# M3HM register map
File version: 0.1
Registers are 32-bit, read-write, reset 0x0 unless marked. A register's access mark holds for its fields unless they carry their own. Offsets are from the block's base; [hi:lo] are bit positions; {n}, {i} and the like mark numbered series.

## PG — Port G
Base 0x400C0600
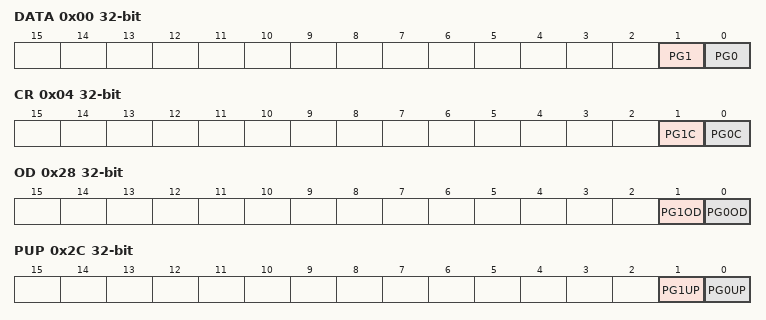
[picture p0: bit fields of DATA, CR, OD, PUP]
0x00 DATA — PG Data Register
  [1] PG1, [0] PG0
0x04 CR — PG Control Register
  [1] PG1C, [0] PG0C
0x28 OD — PG Open Drain Control Register
  [1] PG1OD, [0] PG0OD
0x2C PUP — PG Pull-up Control Register
  [1] PG1UP, [0] PG0UP
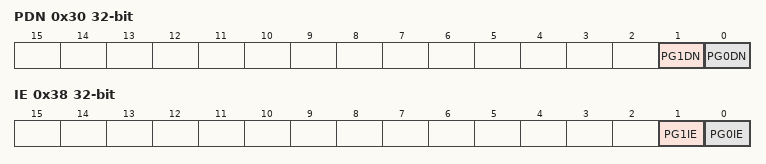
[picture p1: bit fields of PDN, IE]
0x30 PDN — PG Pull-Down Control Register
  [1] PG1DN, [0] PG0DN
0x38 IE — PG Input Enable Control Register
  [1] PG1IE, [0] PG0IE

## PH — Port H
Base 0x400C0700
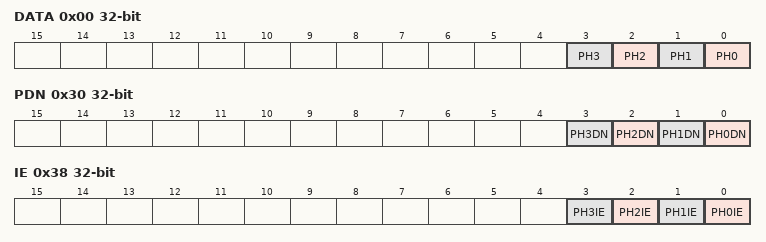
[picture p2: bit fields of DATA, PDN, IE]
0x00 DATA — PH Data Register
  [n] PH{n} (n=0..3)
0x30 PDN — PH Pull-Down Control Register
  [n] PH{n}DN (n=0..3)
0x38 IE — PH Input Enable Control Register
  [n] PH{n}IE (n=0..3)

## PJ — Port J
Base 0x400C0800
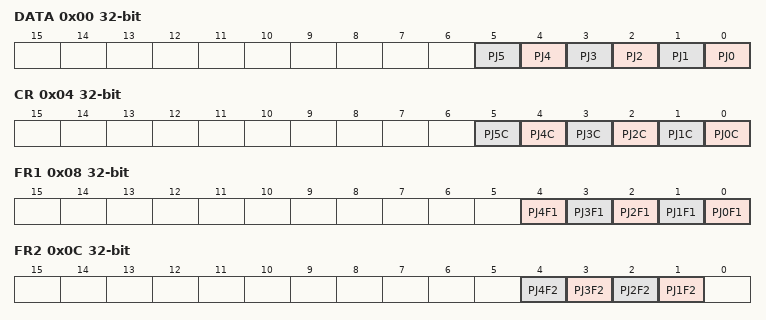
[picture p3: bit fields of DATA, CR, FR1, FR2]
0x00 DATA — PJ Data Register
  [n] PJ{n} (n=0..5)
0x04 CR — PJ Control Register
  [n] PJ{n}C (n=0..5)
0x08 FR1 — PJ Function Register 1
  [n] PJ{n}F1 (n=0..4)
0x0C FR2 — PJ Function Register 2
  [n] PJ{n}F2 (n=1..4)
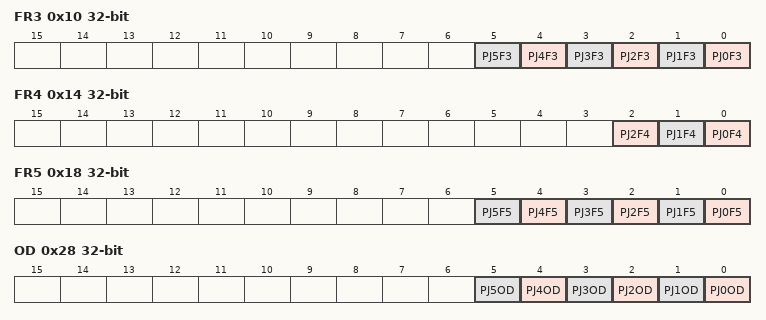
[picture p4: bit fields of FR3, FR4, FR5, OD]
0x10 FR3 — PJ Function Register 3
  [n] PJ{n}F3 (n=0..5)
0x14 FR4 — PJ Function Register 4
  [2] PJ2F4, [1] PJ1F4, [0] PJ0F4
0x18 FR5 — PJ Function Register 5
  [n] PJ{n}F5 (n=0..5)
0x28 OD — PJ Open Drain Control Register
  [n] PJ{n}OD (n=0..5)
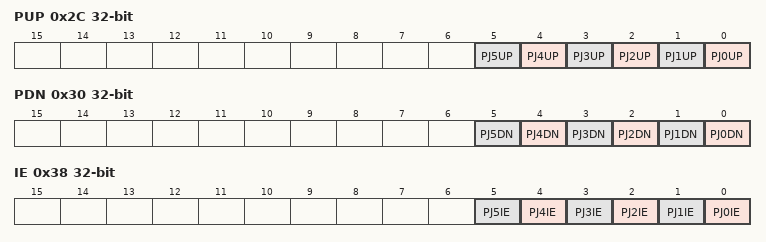
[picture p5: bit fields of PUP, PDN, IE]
0x2C PUP — PJ Pull-up Control Register
  [n] PJ{n}UP (n=0..5)
0x30 PDN — PJ Pull-Down Control Register
  [n] PJ{n}DN (n=0..5)
0x38 IE — PJ Input Enable Control Register
  [n] PJ{n}IE (n=0..5)

## PK — Port K
Base 0x400C0900
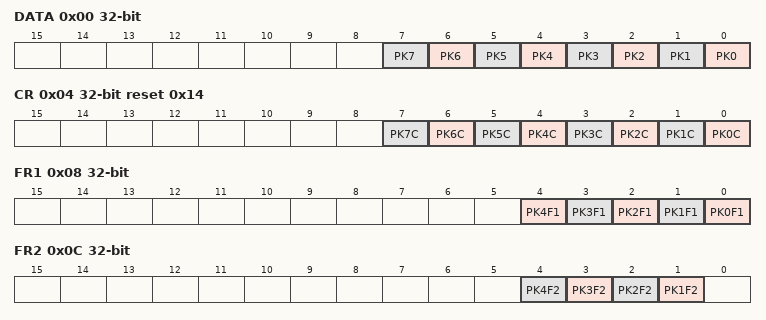
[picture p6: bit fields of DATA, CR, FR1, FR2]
0x00 DATA — PK Data Register
  [n] PK{n} (n=0..7)
0x04 CR reset 0x14 — PK Control Register
  [n] PK{n}C (n=0..7)
0x08 FR1 — PK Function Register 1
  [n] PK{n}F1 (n=0..4)
0x0C FR2 — PK Function Register 2
  [n] PK{n}F2 (n=1..4)
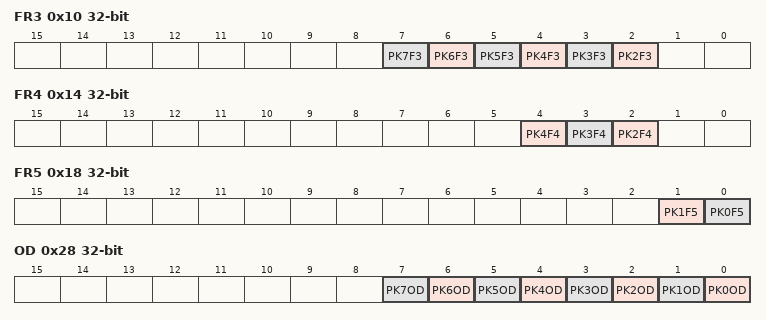
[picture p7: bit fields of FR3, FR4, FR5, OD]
0x10 FR3 — PK Function Register 3
  [n] PK{n}F3 (n=2..7)
0x14 FR4 — PK Function Register 4
  [4] PK4F4, [3] PK3F4, [2] PK2F4
0x18 FR5 — PK Function Register 5
  [1] PK1F5, [0] PK0F5
0x28 OD — PK Open Drain Control Register
  [n] PK{n}OD (n=0..7)
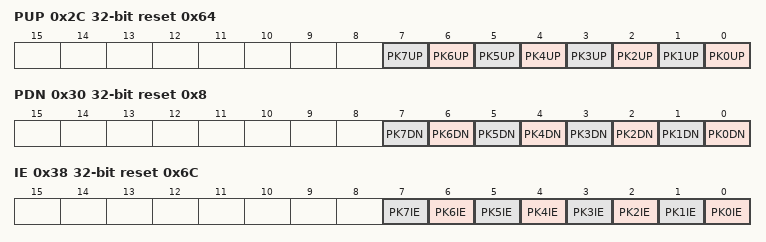
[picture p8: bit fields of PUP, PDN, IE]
0x2C PUP reset 0x64 — PK Pull-up Control Register
  [n] PK{n}UP (n=0..7)
0x30 PDN reset 0x8 — PK Pull-Down Control Register
  [n] PK{n}DN (n=0..7)
0x38 IE reset 0x6C — PK Input Enable Control Register
  [n] PK{n}IE (n=0..7)

## PL — Port L
Base 0x400C0A00
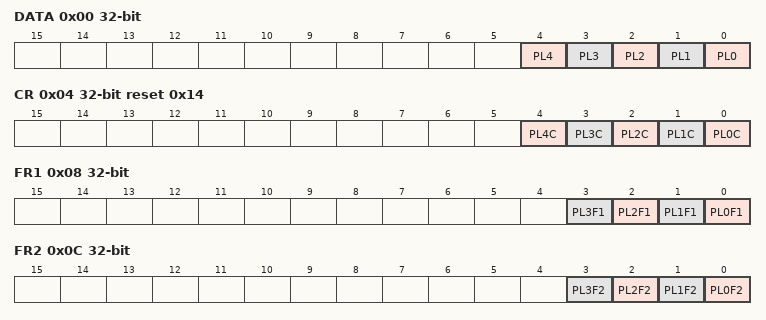
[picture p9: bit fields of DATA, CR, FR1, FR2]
0x00 DATA — PL Data Register
  [n] PL{n} (n=0..4)
0x04 CR reset 0x14 — PL Control Register
  [n] PL{n}C (n=0..4)
0x08 FR1 — PL Function Register 1
  [n] PL{n}F1 (n=0..3)
0x0C FR2 — PL Function Register 2
  [n] PL{n}F2 (n=0..3)
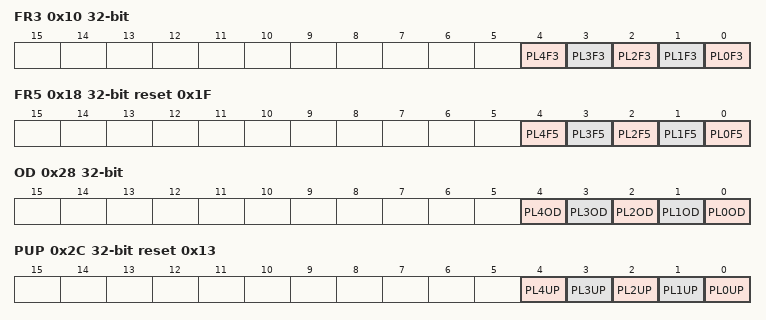
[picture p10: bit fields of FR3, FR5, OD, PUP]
0x10 FR3 — PL Function Register 3
  [n] PL{n}F3 (n=0..4)
0x14 FR4 — PL Function Register 4
0x18 FR5 reset 0x1F — PL Function Register 4
  [n] PL{n}F5 (n=0..4)
0x28 OD — PL Open Drain Control Register
  [n] PL{n}OD (n=0..4)
0x2C PUP reset 0x13 — PL Pull-up Control Register
  [n] PL{n}UP (n=0..4)
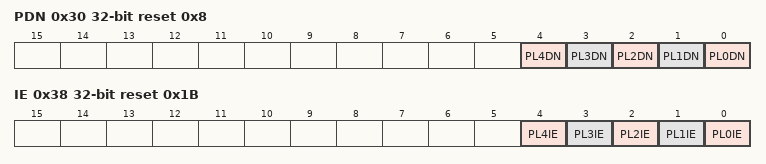
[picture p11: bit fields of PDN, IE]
0x30 PDN reset 0x8 — PL Pull-Down Control Register
  [n] PL{n}DN (n=0..4)
0x38 IE reset 0x1B — PL Input Enable Control Register
  [n] PL{n}IE (n=0..4)

## PM — Port M
Base 0x400C0B00
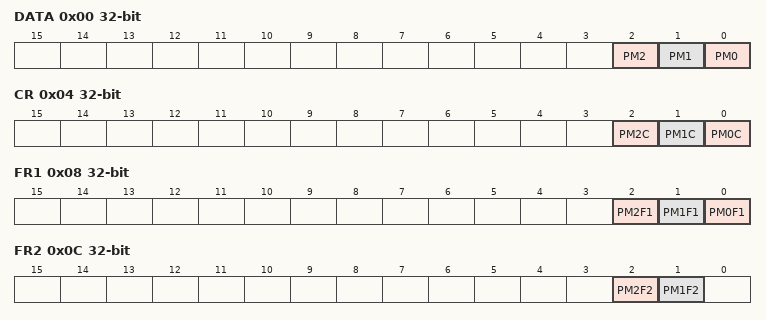
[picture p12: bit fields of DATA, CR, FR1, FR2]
0x00 DATA — PM Data Register
  [2] PM2, [1] PM1, [0] PM0
0x04 CR — PM Control Register
  [2] PM2C, [1] PM1C, [0] PM0C
0x08 FR1 — PM Function Register 1
  [2] PM2F1, [1] PM1F1, [0] PM0F1
0x0C FR2 — PM Function Register 2
  [2] PM2F2, [1] PM1F2
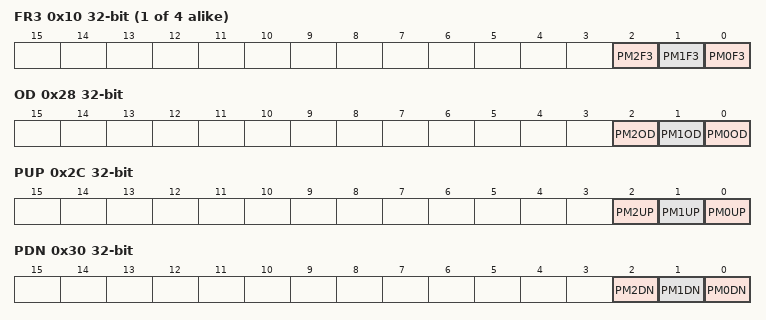
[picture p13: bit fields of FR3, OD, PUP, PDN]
{0x4+4i} FR{i} (i=3..6) — PM Function Register {i}
  [2] PM2F{i}, [1] PM1F{i}, [0] PM0F{i}
0x28 OD — PM Open Drain Control Register
  [2] PM2OD, [1] PM1OD, [0] PM0OD
0x2C PUP — PM Pull-up Control Register
  [2] PM2UP, [1] PM1UP, [0] PM0UP
0x30 PDN — PM Pull-Down Control Register
  [2] PM2DN, [1] PM1DN, [0] PM0DN
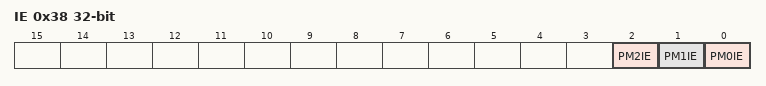
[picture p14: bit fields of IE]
0x38 IE — PM Input Enable Control Register
  [2] PM2IE, [1] PM1IE, [0] PM0IE

## PN — Port N
Base 0x400C0C00
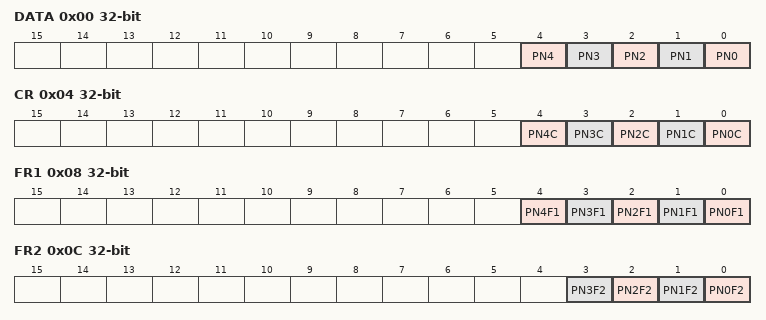
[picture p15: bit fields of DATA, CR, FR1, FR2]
0x00 DATA — PN Data Register
  [n] PN{n} (n=0..4)
0x04 CR — PN Control Register
  [n] PN{n}C (n=0..4)
0x08 FR1 — PN Function Register 1
  [n] PN{n}F1 (n=0..4)
0x0C FR2 — PN Function Register 2
  [n] PN{n}F2 (n=0..3)
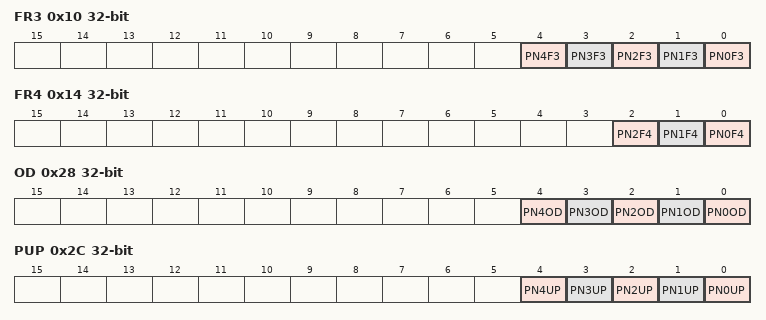
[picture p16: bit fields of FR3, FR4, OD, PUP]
0x10 FR3 — PN Function Register 3
  [n] PN{n}F3 (n=0..4)
0x14 FR4 — PN Function Register 4
  [2] PN2F4, [1] PN1F4, [0] PN0F4
0x18 FR5 — PN Function Register 5
  [3] PN3F5
0x28 OD — PN Open Drain Control Register
  [n] PN{n}OD (n=0..4)
0x2C PUP — PN Pull-up Control Register
  [n] PN{n}UP (n=0..4)
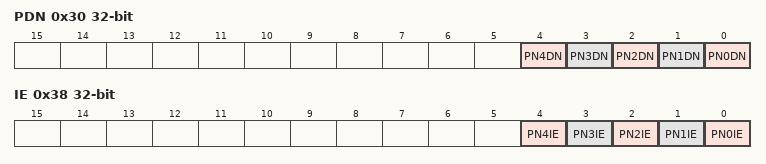
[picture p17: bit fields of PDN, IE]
0x30 PDN — PN Pull-Down Control Register
  [n] PN{n}DN (n=0..4)
0x38 IE — PN Input Enable Control Register
  [n] PN{n}IE (n=0..4)
